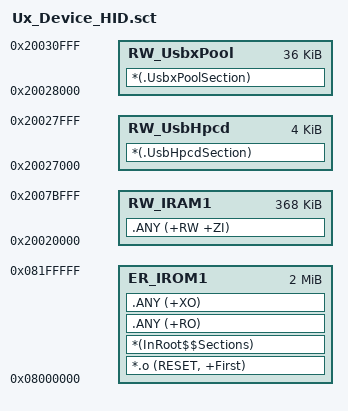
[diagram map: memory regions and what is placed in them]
; *************************************************************
; *** Scatter-Loading Description File generated by uVision ***
; *************************************************************

LR_IROM1 0x08000000 0x00200000  {    ; load region size_region
  ER_IROM1 0x08000000 0x00200000  {  ; load address = execution address
   *.o (RESET, +First)
   *(InRoot$$Sections)
   .ANY (+RO)
   .ANY (+XO)
  }
  RW_IRAM1 0x20020000 0x0005C000  {  ; RW data
   .ANY (+RW +ZI)
  }
  RW_UsbHpcd 0x20027000 0x1000 {
  *(.UsbHpcdSection)
  }
  RW_UsbxPool 0x20028000 0x9000 {
  *(.UsbxPoolSection)
  }
}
